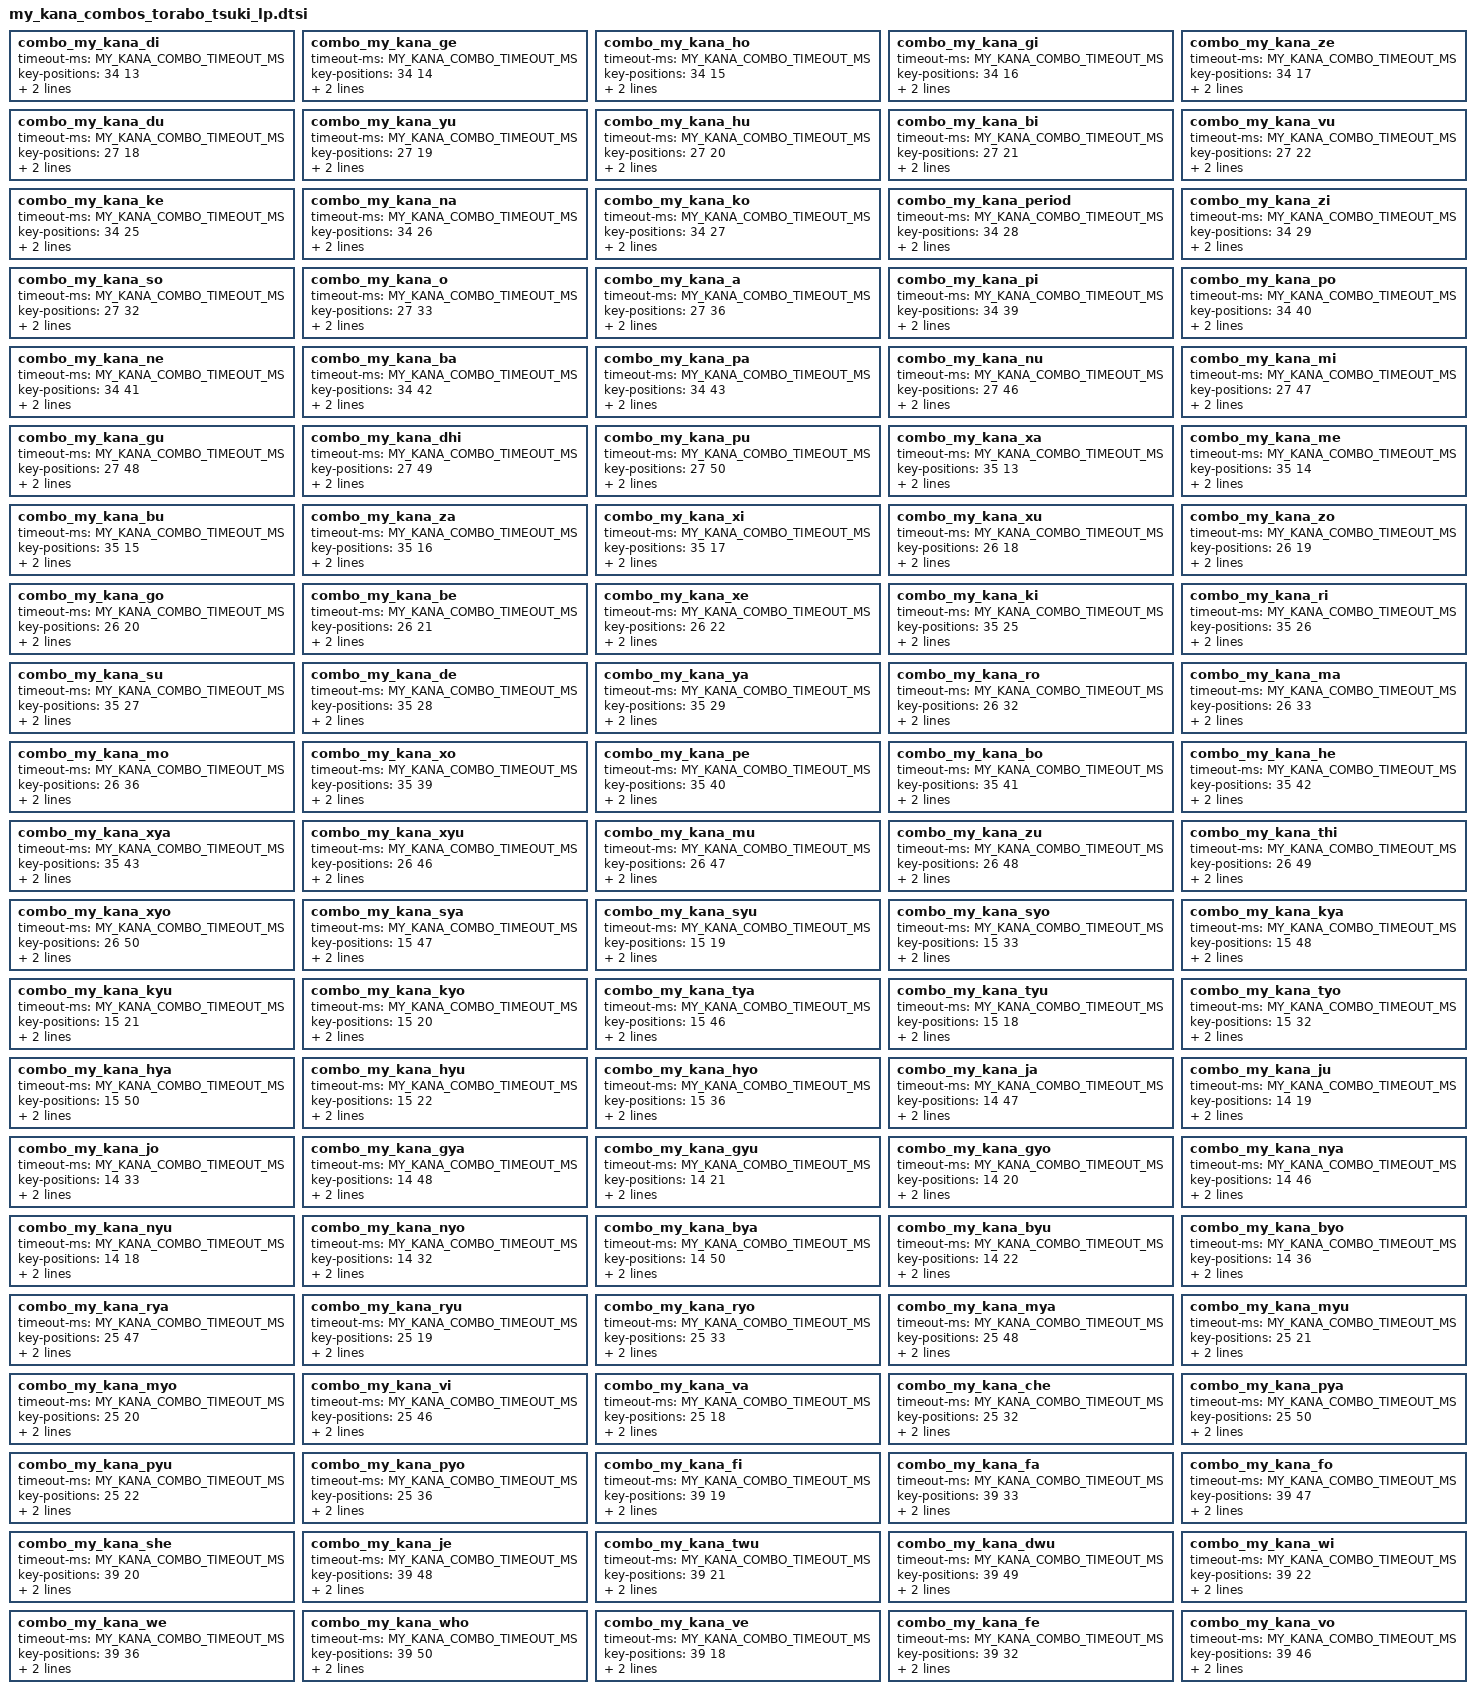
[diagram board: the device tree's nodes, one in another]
// Generated by tools/generate_my_kana_zmk.py. Do not edit manually.

        combo_my_kana_di {
            timeout-ms = <MY_KANA_COMBO_TIMEOUT_MS>;
            key-positions = <34 13>;
            layers = <KANA>;
            bindings = <&my_kana_di_combo>;
        };

        combo_my_kana_ge {
            timeout-ms = <MY_KANA_COMBO_TIMEOUT_MS>;
            key-positions = <34 14>;
            layers = <KANA>;
            bindings = <&my_kana_ge_combo>;
        };

        combo_my_kana_ho {
            timeout-ms = <MY_KANA_COMBO_TIMEOUT_MS>;
            key-positions = <34 15>;
            layers = <KANA>;
            bindings = <&my_kana_ho_combo>;
        };

        combo_my_kana_gi {
            timeout-ms = <MY_KANA_COMBO_TIMEOUT_MS>;
            key-positions = <34 16>;
            layers = <KANA>;
            bindings = <&my_kana_gi_combo>;
        };

        combo_my_kana_ze {
            timeout-ms = <MY_KANA_COMBO_TIMEOUT_MS>;
            key-positions = <34 17>;
            layers = <KANA>;
            bindings = <&my_kana_ze_combo>;
        };

        combo_my_kana_du {
            timeout-ms = <MY_KANA_COMBO_TIMEOUT_MS>;
            key-positions = <27 18>;
            layers = <KANA>;
            bindings = <&my_kana_du_combo>;
        };

        combo_my_kana_yu {
            timeout-ms = <MY_KANA_COMBO_TIMEOUT_MS>;
            key-positions = <27 19>;
            layers = <KANA>;
            bindings = <&my_kana_yu_combo>;
        };

        combo_my_kana_hu {
            timeout-ms = <MY_KANA_COMBO_TIMEOUT_MS>;
            key-positions = <27 20>;
            layers = <KANA>;
            bindings = <&my_kana_hu_combo>;
        };

        combo_my_kana_bi {
            timeout-ms = <MY_KANA_COMBO_TIMEOUT_MS>;
            key-positions = <27 21>;
            layers = <KANA>;
            bindings = <&my_kana_bi_combo>;
        };

        combo_my_kana_vu {
            timeout-ms = <MY_KANA_COMBO_TIMEOUT_MS>;
            key-positions = <27 22>;
            layers = <KANA>;
            bindings = <&my_kana_vu_combo>;
        };

        combo_my_kana_ke {
            timeout-ms = <MY_KANA_COMBO_TIMEOUT_MS>;
            key-positions = <34 25>;
            layers = <KANA>;
            bindings = <&my_kana_ke_combo>;
        };

        combo_my_kana_na {
            timeout-ms = <MY_KANA_COMBO_TIMEOUT_MS>;
            key-positions = <34 26>;
            layers = <KANA>;
            bindings = <&my_kana_na_combo>;
        };

        combo_my_kana_ko {
            timeout-ms = <MY_KANA_COMBO_TIMEOUT_MS>;
            key-positions = <34 27>;
            layers = <KANA>;
            bindings = <&my_kana_ko_combo>;
        };

        combo_my_kana_period {
            timeout-ms = <MY_KANA_COMBO_TIMEOUT_MS>;
            key-positions = <34 28>;
            layers = <KANA>;
            bindings = <&my_kana_period_combo>;
        };

        combo_my_kana_zi {
            timeout-ms = <MY_KANA_COMBO_TIMEOUT_MS>;
            key-positions = <34 29>;
            layers = <KANA>;
            bindings = <&my_kana_zi_combo>;
        };

        combo_my_kana_so {
            timeout-ms = <MY_KANA_COMBO_TIMEOUT_MS>;
            key-positions = <27 32>;
            layers = <KANA>;
            bindings = <&my_kana_so_combo>;
        };

        combo_my_kana_o {
            timeout-ms = <MY_KANA_COMBO_TIMEOUT_MS>;
            key-positions = <27 33>;
            layers = <KANA>;
            bindings = <&my_kana_o_combo>;
        };

        combo_my_kana_a {
            timeout-ms = <MY_KANA_COMBO_TIMEOUT_MS>;
            key-positions = <27 36>;
            layers = <KANA>;
            bindings = <&my_kana_a_combo>;
        };

        combo_my_kana_pi {
            timeout-ms = <MY_KANA_COMBO_TIMEOUT_MS>;
            key-positions = <34 39>;
            layers = <KANA>;
            bindings = <&my_kana_pi_combo>;
        };

        combo_my_kana_po {
            timeout-ms = <MY_KANA_COMBO_TIMEOUT_MS>;
            key-positions = <34 40>;
            layers = <KANA>;
            bindings = <&my_kana_po_combo>;
        };

        combo_my_kana_ne {
            timeout-ms = <MY_KANA_COMBO_TIMEOUT_MS>;
            key-positions = <34 41>;
            layers = <KANA>;
            bindings = <&my_kana_ne_combo>;
        };

        combo_my_kana_ba {
            timeout-ms = <MY_KANA_COMBO_TIMEOUT_MS>;
            key-positions = <34 42>;
            layers = <KANA>;
            bindings = <&my_kana_ba_combo>;
        };

        combo_my_kana_pa {
            timeout-ms = <MY_KANA_COMBO_TIMEOUT_MS>;
            key-positions = <34 43>;
            layers = <KANA>;
            bindings = <&my_kana_pa_combo>;
        };

        combo_my_kana_nu {
            timeout-ms = <MY_KANA_COMBO_TIMEOUT_MS>;
            key-positions = <27 46>;
            layers = <KANA>;
            bindings = <&my_kana_nu_combo>;
        };

        combo_my_kana_mi {
            timeout-ms = <MY_KANA_COMBO_TIMEOUT_MS>;
            key-positions = <27 47>;
            layers = <KANA>;
            bindings = <&my_kana_mi_combo>;
        };

        combo_my_kana_gu {
            timeout-ms = <MY_KANA_COMBO_TIMEOUT_MS>;
            key-positions = <27 48>;
            layers = <KANA>;
            bindings = <&my_kana_gu_combo>;
        };

        combo_my_kana_dhi {
            timeout-ms = <MY_KANA_COMBO_TIMEOUT_MS>;
            key-positions = <27 49>;
            layers = <KANA>;
            bindings = <&my_kana_dhi_combo>;
        };

        combo_my_kana_pu {
            timeout-ms = <MY_KANA_COMBO_TIMEOUT_MS>;
            key-positions = <27 50>;
            layers = <KANA>;
            bindings = <&my_kana_pu_combo>;
        };

        combo_my_kana_xa {
            timeout-ms = <MY_KANA_COMBO_TIMEOUT_MS>;
            key-positions = <35 13>;
            layers = <KANA>;
            bindings = <&my_kana_xa_combo>;
        };

        combo_my_kana_me {
            timeout-ms = <MY_KANA_COMBO_TIMEOUT_MS>;
            key-positions = <35 14>;
            layers = <KANA>;
            bindings = <&my_kana_me_combo>;
        };

        combo_my_kana_bu {
            timeout-ms = <MY_KANA_COMBO_TIMEOUT_MS>;
            key-positions = <35 15>;
            layers = <KANA>;
            bindings = <&my_kana_bu_combo>;
        };

        combo_my_kana_za {
            timeout-ms = <MY_KANA_COMBO_TIMEOUT_MS>;
            key-positions = <35 16>;
            layers = <KANA>;
            bindings = <&my_kana_za_combo>;
        };

        combo_my_kana_xi {
            timeout-ms = <MY_KANA_COMBO_TIMEOUT_MS>;
            key-positions = <35 17>;
            layers = <KANA>;
            bindings = <&my_kana_xi_combo>;
        };

        combo_my_kana_xu {
            timeout-ms = <MY_KANA_COMBO_TIMEOUT_MS>;
            key-positions = <26 18>;
            layers = <KANA>;
            bindings = <&my_kana_xu_combo>;
        };

        combo_my_kana_zo {
            timeout-ms = <MY_KANA_COMBO_TIMEOUT_MS>;
            key-positions = <26 19>;
            layers = <KANA>;
            bindings = <&my_kana_zo_combo>;
        };

        combo_my_kana_go {
            timeout-ms = <MY_KANA_COMBO_TIMEOUT_MS>;
            key-positions = <26 20>;
            layers = <KANA>;
            bindings = <&my_kana_go_combo>;
        };

        combo_my_kana_be {
            timeout-ms = <MY_KANA_COMBO_TIMEOUT_MS>;
            key-positions = <26 21>;
            layers = <KANA>;
            bindings = <&my_kana_be_combo>;
        };

        combo_my_kana_xe {
            timeout-ms = <MY_KANA_COMBO_TIMEOUT_MS>;
            key-positions = <26 22>;
            layers = <KANA>;
            bindings = <&my_kana_xe_combo>;
        };

        combo_my_kana_ki {
            timeout-ms = <MY_KANA_COMBO_TIMEOUT_MS>;
            key-positions = <35 25>;
            layers = <KANA>;
            bindings = <&my_kana_ki_combo>;
        };

        combo_my_kana_ri {
            timeout-ms = <MY_KANA_COMBO_TIMEOUT_MS>;
            key-positions = <35 26>;
            layers = <KANA>;
            bindings = <&my_kana_ri_combo>;
        };

        combo_my_kana_su {
            timeout-ms = <MY_KANA_COMBO_TIMEOUT_MS>;
            key-positions = <35 27>;
            layers = <KANA>;
            bindings = <&my_kana_su_combo>;
        };

        combo_my_kana_de {
            timeout-ms = <MY_KANA_COMBO_TIMEOUT_MS>;
            key-positions = <35 28>;
            layers = <KANA>;
            bindings = <&my_kana_de_combo>;
        };

        combo_my_kana_ya {
            timeout-ms = <MY_KANA_COMBO_TIMEOUT_MS>;
            key-positions = <35 29>;
            layers = <KANA>;
            bindings = <&my_kana_ya_combo>;
        };

        combo_my_kana_ro {
            timeout-ms = <MY_KANA_COMBO_TIMEOUT_MS>;
            key-positions = <26 32>;
            layers = <KANA>;
            bindings = <&my_kana_ro_combo>;
        };

        combo_my_kana_ma {
            timeout-ms = <MY_KANA_COMBO_TIMEOUT_MS>;
            key-positions = <26 33>;
            layers = <KANA>;
            bindings = <&my_kana_ma_combo>;
        };

        combo_my_kana_mo {
            timeout-ms = <MY_KANA_COMBO_TIMEOUT_MS>;
            key-positions = <26 36>;
            layers = <KANA>;
            bindings = <&my_kana_mo_combo>;
        };

        combo_my_kana_xo {
            timeout-ms = <MY_KANA_COMBO_TIMEOUT_MS>;
            key-positions = <35 39>;
            layers = <KANA>;
            bindings = <&my_kana_xo_combo>;
        };

        combo_my_kana_pe {
            timeout-ms = <MY_KANA_COMBO_TIMEOUT_MS>;
            key-positions = <35 40>;
            layers = <KANA>;
            bindings = <&my_kana_pe_combo>;
        };

        combo_my_kana_bo {
            timeout-ms = <MY_KANA_COMBO_TIMEOUT_MS>;
            key-positions = <35 41>;
            layers = <KANA>;
            bindings = <&my_kana_bo_combo>;
        };

        combo_my_kana_he {
            timeout-ms = <MY_KANA_COMBO_TIMEOUT_MS>;
            key-positions = <35 42>;
            layers = <KANA>;
            bindings = <&my_kana_he_combo>;
        };

        combo_my_kana_xya {
            timeout-ms = <MY_KANA_COMBO_TIMEOUT_MS>;
            key-positions = <35 43>;
            layers = <KANA>;
            bindings = <&my_kana_xya_combo>;
        };

        combo_my_kana_xyu {
            timeout-ms = <MY_KANA_COMBO_TIMEOUT_MS>;
            key-positions = <26 46>;
            layers = <KANA>;
            bindings = <&my_kana_xyu_combo>;
        };

        combo_my_kana_mu {
            timeout-ms = <MY_KANA_COMBO_TIMEOUT_MS>;
            key-positions = <26 47>;
            layers = <KANA>;
            bindings = <&my_kana_mu_combo>;
        };

        combo_my_kana_zu {
            timeout-ms = <MY_KANA_COMBO_TIMEOUT_MS>;
            key-positions = <26 48>;
            layers = <KANA>;
            bindings = <&my_kana_zu_combo>;
        };

        combo_my_kana_thi {
            timeout-ms = <MY_KANA_COMBO_TIMEOUT_MS>;
            key-positions = <26 49>;
            layers = <KANA>;
            bindings = <&my_kana_thi_combo>;
        };

        combo_my_kana_xyo {
            timeout-ms = <MY_KANA_COMBO_TIMEOUT_MS>;
            key-positions = <26 50>;
            layers = <KANA>;
            bindings = <&my_kana_xyo_combo>;
        };

        combo_my_kana_sya {
            timeout-ms = <MY_KANA_COMBO_TIMEOUT_MS>;
            key-positions = <15 47>;
            layers = <KANA>;
            bindings = <&my_kana_sya_combo>;
        };

        combo_my_kana_syu {
            timeout-ms = <MY_KANA_COMBO_TIMEOUT_MS>;
            key-positions = <15 19>;
            layers = <KANA>;
            bindings = <&my_kana_syu_combo>;
        };

        combo_my_kana_syo {
            timeout-ms = <MY_KANA_COMBO_TIMEOUT_MS>;
            key-positions = <15 33>;
            layers = <KANA>;
            bindings = <&my_kana_syo_combo>;
        };

        combo_my_kana_kya {
            timeout-ms = <MY_KANA_COMBO_TIMEOUT_MS>;
            key-positions = <15 48>;
            layers = <KANA>;
            bindings = <&my_kana_kya_combo>;
        };

        combo_my_kana_kyu {
            timeout-ms = <MY_KANA_COMBO_TIMEOUT_MS>;
            key-positions = <15 21>;
            layers = <KANA>;
            bindings = <&my_kana_kyu_combo>;
        };

        combo_my_kana_kyo {
            timeout-ms = <MY_KANA_COMBO_TIMEOUT_MS>;
            key-positions = <15 20>;
            layers = <KANA>;
            bindings = <&my_kana_kyo_combo>;
        };

        combo_my_kana_tya {
            timeout-ms = <MY_KANA_COMBO_TIMEOUT_MS>;
            key-positions = <15 46>;
            layers = <KANA>;
            bindings = <&my_kana_tya_combo>;
        };

        combo_my_kana_tyu {
            timeout-ms = <MY_KANA_COMBO_TIMEOUT_MS>;
            key-positions = <15 18>;
            layers = <KANA>;
            bindings = <&my_kana_tyu_combo>;
        };

        combo_my_kana_tyo {
            timeout-ms = <MY_KANA_COMBO_TIMEOUT_MS>;
            key-positions = <15 32>;
            layers = <KANA>;
            bindings = <&my_kana_tyo_combo>;
        };

        combo_my_kana_hya {
            timeout-ms = <MY_KANA_COMBO_TIMEOUT_MS>;
            key-positions = <15 50>;
            layers = <KANA>;
            bindings = <&my_kana_hya_combo>;
        };

        combo_my_kana_hyu {
            timeout-ms = <MY_KANA_COMBO_TIMEOUT_MS>;
            key-positions = <15 22>;
            layers = <KANA>;
            bindings = <&my_kana_hyu_combo>;
        };

        combo_my_kana_hyo {
            timeout-ms = <MY_KANA_COMBO_TIMEOUT_MS>;
            key-positions = <15 36>;
            layers = <KANA>;
            bindings = <&my_kana_hyo_combo>;
        };

        combo_my_kana_ja {
            timeout-ms = <MY_KANA_COMBO_TIMEOUT_MS>;
            key-positions = <14 47>;
            layers = <KANA>;
            bindings = <&my_kana_ja_combo>;
        };

        combo_my_kana_ju {
            timeout-ms = <MY_KANA_COMBO_TIMEOUT_MS>;
            key-positions = <14 19>;
            layers = <KANA>;
            bindings = <&my_kana_ju_combo>;
        };

        combo_my_kana_jo {
            timeout-ms = <MY_KANA_COMBO_TIMEOUT_MS>;
            key-positions = <14 33>;
            layers = <KANA>;
            bindings = <&my_kana_jo_combo>;
        };

        combo_my_kana_gya {
            timeout-ms = <MY_KANA_COMBO_TIMEOUT_MS>;
            key-positions = <14 48>;
            layers = <KANA>;
            bindings = <&my_kana_gya_combo>;
        };

        combo_my_kana_gyu {
            timeout-ms = <MY_KANA_COMBO_TIMEOUT_MS>;
            key-positions = <14 21>;
            layers = <KANA>;
            bindings = <&my_kana_gyu_combo>;
        };

        combo_my_kana_gyo {
            timeout-ms = <MY_KANA_COMBO_TIMEOUT_MS>;
            key-positions = <14 20>;
            layers = <KANA>;
            bindings = <&my_kana_gyo_combo>;
        };

        combo_my_kana_nya {
            timeout-ms = <MY_KANA_COMBO_TIMEOUT_MS>;
            key-positions = <14 46>;
            layers = <KANA>;
            bindings = <&my_kana_nya_combo>;
        };

        combo_my_kana_nyu {
            timeout-ms = <MY_KANA_COMBO_TIMEOUT_MS>;
            key-positions = <14 18>;
            layers = <KANA>;
            bindings = <&my_kana_nyu_combo>;
        };

        combo_my_kana_nyo {
            timeout-ms = <MY_KANA_COMBO_TIMEOUT_MS>;
            key-positions = <14 32>;
            layers = <KANA>;
            bindings = <&my_kana_nyo_combo>;
        };

        combo_my_kana_bya {
            timeout-ms = <MY_KANA_COMBO_TIMEOUT_MS>;
            key-positions = <14 50>;
            layers = <KANA>;
            bindings = <&my_kana_bya_combo>;
        };

        combo_my_kana_byu {
            timeout-ms = <MY_KANA_COMBO_TIMEOUT_MS>;
            key-positions = <14 22>;
            layers = <KANA>;
            bindings = <&my_kana_byu_combo>;
        };

        combo_my_kana_byo {
            timeout-ms = <MY_KANA_COMBO_TIMEOUT_MS>;
            key-positions = <14 36>;
            layers = <KANA>;
            bindings = <&my_kana_byo_combo>;
        };

        combo_my_kana_rya {
            timeout-ms = <MY_KANA_COMBO_TIMEOUT_MS>;
            key-positions = <25 47>;
            layers = <KANA>;
            bindings = <&my_kana_rya_combo>;
        };

        combo_my_kana_ryu {
            timeout-ms = <MY_KANA_COMBO_TIMEOUT_MS>;
            key-positions = <25 19>;
            layers = <KANA>;
            bindings = <&my_kana_ryu_combo>;
        };

        combo_my_kana_ryo {
            timeout-ms = <MY_KANA_COMBO_TIMEOUT_MS>;
            key-positions = <25 33>;
            layers = <KANA>;
            bindings = <&my_kana_ryo_combo>;
        };

        combo_my_kana_mya {
            timeout-ms = <MY_KANA_COMBO_TIMEOUT_MS>;
            key-positions = <25 48>;
            layers = <KANA>;
            bindings = <&my_kana_mya_combo>;
        };

        combo_my_kana_myu {
            timeout-ms = <MY_KANA_COMBO_TIMEOUT_MS>;
            key-positions = <25 21>;
            layers = <KANA>;
            bindings = <&my_kana_myu_combo>;
        };

        combo_my_kana_myo {
            timeout-ms = <MY_KANA_COMBO_TIMEOUT_MS>;
            key-positions = <25 20>;
            layers = <KANA>;
            bindings = <&my_kana_myo_combo>;
        };

        combo_my_kana_vi {
            timeout-ms = <MY_KANA_COMBO_TIMEOUT_MS>;
            key-positions = <25 46>;
            layers = <KANA>;
            bindings = <&my_kana_vi_combo>;
        };

        combo_my_kana_va {
            timeout-ms = <MY_KANA_COMBO_TIMEOUT_MS>;
            key-positions = <25 18>;
            layers = <KANA>;
            bindings = <&my_kana_va_combo>;
        };

        combo_my_kana_che {
            timeout-ms = <MY_KANA_COMBO_TIMEOUT_MS>;
            key-positions = <25 32>;
            layers = <KANA>;
            bindings = <&my_kana_che_combo>;
        };

        combo_my_kana_pya {
            timeout-ms = <MY_KANA_COMBO_TIMEOUT_MS>;
            key-positions = <25 50>;
            layers = <KANA>;
            bindings = <&my_kana_pya_combo>;
        };

        combo_my_kana_pyu {
            timeout-ms = <MY_KANA_COMBO_TIMEOUT_MS>;
            key-positions = <25 22>;
            layers = <KANA>;
            bindings = <&my_kana_pyu_combo>;
        };

        combo_my_kana_pyo {
            timeout-ms = <MY_KANA_COMBO_TIMEOUT_MS>;
            key-positions = <25 36>;
            layers = <KANA>;
            bindings = <&my_kana_pyo_combo>;
        };

        combo_my_kana_fi {
            timeout-ms = <MY_KANA_COMBO_TIMEOUT_MS>;
            key-positions = <39 19>;
            layers = <KANA>;
            bindings = <&my_kana_fi_combo>;
        };

        combo_my_kana_fa {
            timeout-ms = <MY_KANA_COMBO_TIMEOUT_MS>;
            key-positions = <39 33>;
            layers = <KANA>;
            bindings = <&my_kana_fa_combo>;
        };

        combo_my_kana_fo {
            timeout-ms = <MY_KANA_COMBO_TIMEOUT_MS>;
            key-positions = <39 47>;
            layers = <KANA>;
            bindings = <&my_kana_fo_combo>;
        };

        combo_my_kana_she {
            timeout-ms = <MY_KANA_COMBO_TIMEOUT_MS>;
            key-positions = <39 20>;
            layers = <KANA>;
            bindings = <&my_kana_she_combo>;
        };

        combo_my_kana_je {
            timeout-ms = <MY_KANA_COMBO_TIMEOUT_MS>;
            key-positions = <39 48>;
            layers = <KANA>;
            bindings = <&my_kana_je_combo>;
        };

        combo_my_kana_twu {
            timeout-ms = <MY_KANA_COMBO_TIMEOUT_MS>;
            key-positions = <39 21>;
            layers = <KANA>;
            bindings = <&my_kana_twu_combo>;
        };

        combo_my_kana_dwu {
            timeout-ms = <MY_KANA_COMBO_TIMEOUT_MS>;
            key-positions = <39 49>;
            layers = <KANA>;
            bindings = <&my_kana_dwu_combo>;
        };

        combo_my_kana_wi {
            timeout-ms = <MY_KANA_COMBO_TIMEOUT_MS>;
            key-positions = <39 22>;
            layers = <KANA>;
            bindings = <&my_kana_wi_combo>;
        };

        combo_my_kana_we {
            timeout-ms = <MY_KANA_COMBO_TIMEOUT_MS>;
            key-positions = <39 36>;
            layers = <KANA>;
            bindings = <&my_kana_we_combo>;
        };

        combo_my_kana_who {
            timeout-ms = <MY_KANA_COMBO_TIMEOUT_MS>;
            key-positions = <39 50>;
            layers = <KANA>;
            bindings = <&my_kana_who_combo>;
        };

        combo_my_kana_ve {
            timeout-ms = <MY_KANA_COMBO_TIMEOUT_MS>;
            key-positions = <39 18>;
            layers = <KANA>;
            bindings = <&my_kana_ve_combo>;
        };

        combo_my_kana_fe {
            timeout-ms = <MY_KANA_COMBO_TIMEOUT_MS>;
            key-positions = <39 32>;
            layers = <KANA>;
            bindings = <&my_kana_fe_combo>;
        };

        combo_my_kana_vo {
            timeout-ms = <MY_KANA_COMBO_TIMEOUT_MS>;
            key-positions = <39 46>;
            layers = <KANA>;
            bindings = <&my_kana_vo_combo>;
        };

